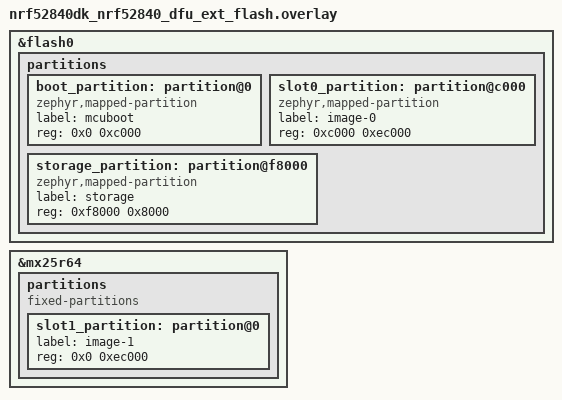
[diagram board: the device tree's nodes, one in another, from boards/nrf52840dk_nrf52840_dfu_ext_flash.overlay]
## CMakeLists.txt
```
# SPDX-License-Identifier: LicenseRef-Nordic-5-Clause

cmake_minimum_required(VERSION 3.13.1)
find_package(Zephyr REQUIRED HINTS $ENV{ZEPHYR_BASE})
project(mesh_dfu_target)

set(dfu_common_dir ${ZEPHYR_NRF_MODULE_DIR}/samples/bluetooth/mesh/dfu/common/src)

include_directories(
  ${dfu_common_dir}
  ${ZEPHYR_NRF_MODULE_DIR}/samples/bluetooth/mesh/common
)

FILE(GLOB app_sources src/*.c)
target_sources(app PRIVATE ${app_sources}
  ${dfu_common_dir}/dfu_target.c
)

target_sources_ifdef(CONFIG_NCS_SAMPLE_MCUMGR_BT_OTA_DFU app PRIVATE
  ${ZEPHYR_NRF_MODULE_DIR}/samples/bluetooth/mesh/common/smp_bt.c
)

target_link_libraries(app PRIVATE MCUBOOT_BOOTUTIL)
```

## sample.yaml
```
sample:
  name: Bluetooth Mesh DFU Target
common:
  tags:
    - bluetooth
    - ci_build
    - sysbuild
    - ci_samples_bluetooth
tests:
  sample.bluetooth.mesh_dfu_target:
    sysbuild: true
    build_only: true
    integration_platforms:
      - nrf54l15dk/nrf54l15/cpuapp
    platform_allow:
      - nrf54l15dk/nrf54l15/cpuapp
      - nrf54l15dk/nrf54l10/cpuapp
      - nrf54lc10dk/nrf54lc10a/cpuapp
      - nrf54lm20dk/nrf54lm20a/cpuapp
  sample.bluetooth.mesh_dfu_target.dfu_ext_flash:
    sysbuild: true
    build_only: true
    integration_platforms:
      - nrf54l15dk/nrf54l15/cpuapp
    platform_allow:
      - nrf54l15dk/nrf54l15/cpuapp
    extra_args: FILE_SUFFIX=dfu_ext_flash
  sample.bluetooth.mesh_dfu_target.settings_ext_flash:
    sysbuild: true
    build_only: true
    integration_platforms:
      - nrf54l15dk/nrf54l15/cpuapp
    platform_allow:
      - nrf54l15dk/nrf54l15/cpuapp
      - nrf54l15dk/nrf54l10/cpuapp
    extra_args: FILE_SUFFIX=settings_ext_flash
```

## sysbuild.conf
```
#
# Copyright (c) 2023 Nordic Semiconductor
#
# SPDX-License-Identifier: LicenseRef-Nordic-5-Clause
#

SB_CONFIG_BOOTLOADER_MCUBOOT=y
SB_CONFIG_MERGED_HEX_FILES=y
SB_CONFIG_DFU_ZIP=y
SB_CONFIG_DFU_ZIP_BLUETOOTH_MESH_METADATA=y
SB_CONFIG_DFU_ZIP_BLUETOOTH_MESH_METADATA_FWID_MCUBOOT_VERSION=y
```

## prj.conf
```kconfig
#
# Copyright (c) 2021 Nordic Semiconductor ASA
#
# SPDX-License-Identifier: LicenseRef-Nordic-5-Clause
#

# General configuration
CONFIG_SYSTEM_WORKQUEUE_STACK_SIZE=2048
CONFIG_FLASH=y
CONFIG_FLASH_MAP=y
CONFIG_NVS=y
CONFIG_SETTINGS=y
CONFIG_NVS_LOOKUP_CACHE=y
CONFIG_SETTINGS_NVS_NAME_CACHE=y
CONFIG_HWINFO=y
CONFIG_DK_LIBRARY=y
CONFIG_BT_MESH_NODE_RESET_BUTTON=y
CONFIG_LOG=y

# Bootloader configuration
CONFIG_NCS_APPLICATION_BOOT_BANNER_STRING="Mesh DFU Target"
CONFIG_STREAM_FLASH=y
CONFIG_BOOTLOADER_MCUBOOT=y
CONFIG_IMG_MANAGER=y
CONFIG_MCUBOOT_IMG_MANAGER=y
CONFIG_MCUBOOT_GENERATE_CONFIRMED_IMAGE=y
CONFIG_MCUBOOT_IMGTOOL_SIGN_VERSION="1.0.0+0"
CONFIG_REBOOT=y

# Bluetooth configuration
CONFIG_BT=y
CONFIG_BT_DEVICE_NAME="Mesh DFU Target"
CONFIG_BT_L2CAP_TX_BUF_COUNT=8
CONFIG_BT_OBSERVER=y
CONFIG_BT_PERIPHERAL=y
CONFIG_BT_SETTINGS=y

# Disable unused Bluetooth features
CONFIG_BT_CTLR_LE_ENC=n
CONFIG_BT_DATA_LEN_UPDATE=n
CONFIG_BT_PHY_UPDATE=n
CONFIG_BT_CTLR_CHAN_SEL_2=n
CONFIG_BT_CTLR_PRIVACY=n

# Bluetooth Mesh configuration
CONFIG_BT_MESH=y
CONFIG_BT_MESH_RELAY=y
CONFIG_BT_MESH_FRIEND=y
CONFIG_BT_MESH_MSG_CACHE_SIZE=256
CONFIG_BT_MESH_ADV_BUF_COUNT=128
CONFIG_BT_MESH_TX_SEG_MAX=14
CONFIG_BT_MESH_RX_SEG_MAX=14
CONFIG_BT_MESH_TX_SEG_MSG_COUNT=2
CONFIG_BT_MESH_RX_SEG_MSG_COUNT=2
CONFIG_BT_MESH_PB_GATT=y
CONFIG_BT_MESH_PB_ADV=y
CONFIG_BT_MESH_GATT_PROXY=y
CONFIG_BT_MESH_DK_PROV=y
CONFIG_BT_MESH_PROXY_USE_DEVICE_NAME=y
CONFIG_BT_MESH_MODEL_EXTENSIONS=y
CONFIG_BT_MESH_MODEL_EXTENSION_LIST_SIZE=1

# Bluetooth Mesh models
CONFIG_BT_MESH_BLOB_SRV=y
CONFIG_BT_MESH_BLOB_IO_FLASH=y
CONFIG_BT_MESH_DFU_SRV=y
CONFIG_BT_MESH_DFU_METADATA=y
CONFIG_BT_MESH_SAR_CFG_SRV=y

# Reconfigure transport SAR for DFU
# Increase probability of delivering segmented messages
CONFIG_BT_MESH_SAR_TX_UNICAST_RETRANS_COUNT=0x5
CONFIG_BT_MESH_SAR_TX_UNICAST_RETRANS_WITHOUT_PROG_COUNT=0x3
# Reduce amount of generated SegAcks
CONFIG_BT_MESH_SAR_RX_ACK_RETRANS_COUNT=0x0
CONFIG_BT_MESH_SAR_RX_ACK_DELAY_INC=0x7
CONFIG_BT_MESH_SAR_RX_SEG_INT_STEP=0xf
CONFIG_BT_MESH_SAR_RX_SEG_THRESHOLD=0x1f

# Debug configuration
CONFIG_BT_MESH_LOG_LEVEL_DBG=y
CONFIG_BT_MESH_MODEL_LOG_LEVEL_DBG=y
CONFIG_BT_MESH_DFU_LOG_LEVEL_DBG=y
CONFIG_BT_MESH_PROVISIONEE_LOG_LEVEL_INF=y

# Link Time Optimization. CONFIG_LTO depends on ISR_TABLES_LOCAL_DECLARATION
CONFIG_LTO=y
CONFIG_ISR_TABLES_LOCAL_DECLARATION=y
```

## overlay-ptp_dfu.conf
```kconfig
#
# Copyright (c) 2024 Nordic Semiconductor ASA
#
# SPDX-License-Identifier: LicenseRef-Nordic-5-Clause
#

# Enable point to point DFU over SMP
CONFIG_NCS_SAMPLE_MCUMGR_BT_OTA_DFU=y
CONFIG_NCS_SAMPLE_MCUMGR_BT_OTA_DFU_SPEEDUP=y

# Increase Extended Advertiser Set to advertise BT SMP service
CONFIG_BT_EXT_ADV_MAX_ADV_SET=6

# One extra connection for mesh GATT/proxy and one for SMP BT.
CONFIG_BT_MAX_CONN=3

# One extra identity for SMP service
CONFIG_BT_ID_MAX=2
```

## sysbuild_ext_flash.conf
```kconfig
#
# Copyright (c) 2025 Nordic Semiconductor ASA
#
# SPDX-License-Identifier: LicenseRef-Nordic-5-Clause
#

SB_CONFIG_BOOTLOADER_MCUBOOT=y
SB_CONFIG_PM_EXTERNAL_FLASH_MCUBOOT_SECONDARY=y
SB_CONFIG_DFU_ZIP=y
SB_CONFIG_DFU_ZIP_BLUETOOTH_MESH_METADATA=y
SB_CONFIG_DFU_ZIP_BLUETOOTH_MESH_METADATA_FWID_MCUBOOT_VERSION=y
```

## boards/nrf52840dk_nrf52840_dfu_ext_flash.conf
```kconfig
#
# Copyright (c) 2026 Nordic Semiconductor ASA
#
# SPDX-License-Identifier: LicenseRef-Nordic-5-Clause
#

# External flash support for nRF52840 DK
CONFIG_NORDIC_QSPI_NOR=y
```

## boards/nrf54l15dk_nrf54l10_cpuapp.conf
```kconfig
#
# Copyright (c) 2024 Nordic Semiconductor ASA
#
# SPDX-License-Identifier: LicenseRef-Nordic-5-Clause
#
################################################################################
# Application overlay - nrf54l10

CONFIG_SOC_FLASH_NRF_PARTIAL_ERASE=n
CONFIG_NVS=n
CONFIG_NVS_LOOKUP_CACHE=n
CONFIG_SETTINGS_NVS_NAME_CACHE=n
CONFIG_ZMS=y
CONFIG_SETTINGS_ZMS_CUSTOM_SECTOR_COUNT=y
CONFIG_SETTINGS_ZMS_SECTOR_COUNT=8
CONFIG_ZMS_LOOKUP_CACHE=y
CONFIG_ZMS_LOOKUP_CACHE_SIZE=512
```

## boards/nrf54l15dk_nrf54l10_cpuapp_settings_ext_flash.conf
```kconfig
#
# Copyright (c) 2025 Nordic Semiconductor ASA
#
# SPDX-License-Identifier: LicenseRef-Nordic-5-Clause
#
################################################################################
# Application overlay - nrf54l10

CONFIG_SOC_FLASH_NRF_PARTIAL_ERASE=n
CONFIG_NVS=n
CONFIG_NVS_LOOKUP_CACHE=n
CONFIG_SETTINGS_NVS_NAME_CACHE=n
CONFIG_ZMS=y
CONFIG_SETTINGS_ZMS_CUSTOM_SECTOR_COUNT=y
CONFIG_SETTINGS_ZMS_SECTOR_COUNT=8
CONFIG_ZMS_LOOKUP_CACHE=y
CONFIG_ZMS_LOOKUP_CACHE_SIZE=512
CONFIG_ZMS_LOOKUP_CACHE_FOR_SETTINGS=y
CONFIG_SYSTEM_WORKQUEUE_STACK_SIZE=4096
CONFIG_BT_RX_STACK_SIZE=5120
CONFIG_BT_MESH_SETTINGS_WORKQ_STACK_SIZE=1800

# External flash specific settings
CONFIG_GPIO=y
CONFIG_SPI=y
CONFIG_SPI_NOR=y
CONFIG_SPI_NOR_SFDP_DEVICETREE=y
CONFIG_SPI_NOR_FLASH_LAYOUT_PAGE_SIZE=4096
# QSPI drivers are enabled by default for some chips.
# Disable it explicitly to be sure QSPI is disabled.
CONFIG_NORDIC_QSPI_NOR=n
```

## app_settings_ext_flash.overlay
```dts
/* Copyright (c) 2025 Nordic Semiconductor ASA
 *
 * SPDX-License-Identifier: LicenseRef-Nordic-5-Clause
 */

/delete-node/ &storage_partition;

&mx25r64 {
	status = "okay";

	partitions {
		compatible = "fixed-partitions";
		#address-cells = <1>;
		#size-cells = <1>;

		storage_partition: partition@0 {
			label = "storage";
			reg = <0x0 0x8000>;
		};
	};
};
```

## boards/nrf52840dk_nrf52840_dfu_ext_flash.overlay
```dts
/*
 * Copyright (c) 2026 Nordic Semiconductor ASA
 *
 * SPDX-License-Identifier: LicenseRef-Nordic-5-Clause
 */

/delete-node/ &boot_partition;
/delete-node/ &slot0_partition;
/delete-node/ &slot1_partition;
/delete-node/ &storage_partition;

&flash0 {
	partitions {
		boot_partition: partition@0 {
			compatible = "zephyr,mapped-partition";
			label = "mcuboot";
			reg = <0x0 0xc000>;
		};

		slot0_partition: partition@c000 {
			compatible = "zephyr,mapped-partition";
			label = "image-0";
			reg = <0xc000 0xec000>;
		};

		storage_partition: partition@f8000 {
			compatible = "zephyr,mapped-partition";
			label = "storage";
			reg = <0xf8000 0x8000>;
		};
	};
};

&mx25r64 {
	status = "okay";

	partitions {
		compatible = "fixed-partitions";
		#address-cells = <1>;
		#size-cells = <1>;

		slot1_partition: partition@0 {
			label = "image-1";
			reg = <0x0 0xec000>;
		};
	};
};
```

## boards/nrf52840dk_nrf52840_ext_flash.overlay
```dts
/* Copyright (c) 2025 Nordic Semiconductor ASA
 *
 * SPDX-License-Identifier: LicenseRef-Nordic-5-Clause
 */

&mx25r64 {
	status = "okay";
	nordic,pm-ext-flash = &mx25r64;
};
```

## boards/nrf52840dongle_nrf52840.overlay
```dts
/*
 * Copyright (c) 2026 Nordic Semiconductor ASA
 *
 * SPDX-License-Identifier: LicenseRef-Nordic-5-Clause
 */

/delete-node/ &boot_partition;
/delete-node/ &slot0_partition;
/delete-node/ &slot1_partition;
/delete-node/ &storage_partition;

&flash0 {
	partitions {
		nrf5_mbr: partition@0 {
			compatible = "zephyr,mapped-partition";
			label = "nrf5-mbr";
			reg = <0x0 0x1000>;
		};

		boot_partition: partition@1000 {
			compatible = "zephyr,mapped-partition";
			label = "mcuboot";
			reg = <0x1000 0x10000>;
		};

		slot0_partition: partition@11000 {
			compatible = "zephyr,mapped-partition";
			label = "image-0";
			reg = <0x11000 0x66000>;
		};

		slot1_partition: partition@77000 {
			compatible = "zephyr,mapped-partition";
			label = "image-1";
			reg = <0x77000 0x66000>;
		};

		storage_partition: partition@dd000 {
			compatible = "zephyr,mapped-partition";
			label = "storage";
			reg = <0xdd000 0x3000>;
		};

		legacy_bootloader_storage: partition@e0000 {
			compatible = "zephyr,mapped-partition";
			label = "legacy-bootloader-storage";
			reg = <0xe0000 0x20000>;
		};
	};
};
```

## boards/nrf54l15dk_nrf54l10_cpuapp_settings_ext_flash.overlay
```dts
/*
 * Copyright (c) 2026 Nordic Semiconductor ASA
 *
 * SPDX-License-Identifier: LicenseRef-Nordic-5-Clause
 */

/delete-node/ &boot_partition;
/delete-node/ &slot0_partition;
/delete-node/ &slot1_partition;
/delete-node/ &storage_partition;

&cpuapp_rram {
	partitions {
		boot_partition: partition@0 {
			compatible = "zephyr,mapped-partition";
			label = "mcuboot";
			reg = <0x0 0xe000>;
		};

		slot0_partition: partition@e000 {
			compatible = "zephyr,mapped-partition";
			label = "image-0";
			reg = <0xe000 0x73000>;
		};

		slot1_partition: partition@81000 {
			compatible = "zephyr,mapped-partition";
			label = "image-1";
			reg = <0x81000 0x73000>;
		};
	};
};

&mx25r64 {
	status = "okay";

	partitions {
		compatible = "fixed-partitions";
		#address-cells = <1>;
		#size-cells = <1>;

		storage_partition: partition@0 {
			label = "storage";
			reg = <0x0 0x8000>;
		};
	};
};
```

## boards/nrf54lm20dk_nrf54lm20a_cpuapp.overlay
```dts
/*
 * Copyright (c) 2026 Nordic Semiconductor ASA
 *
 * SPDX-License-Identifier: LicenseRef-Nordic-5-Clause
 */

/delete-node/ &boot_partition;
/delete-node/ &slot0_partition;
/delete-node/ &slot1_partition;
/delete-node/ &storage_partition;

&cpuapp_rram {
	partitions {
		boot_partition: partition@0 {
			compatible = "zephyr,mapped-partition";
			label = "mcuboot";
			reg = <0x0 0xe000>;
		};

		slot0_partition: partition@e000 {
			compatible = "zephyr,mapped-partition";
			label = "image-0";
			reg = <0xe000 0xe7000>;
		};

		slot1_partition: partition@f5000 {
			compatible = "zephyr,mapped-partition";
			label = "image-1";
			reg = <0xf5000 0xe7000>;
		};

		storage_partition: partition@1dd000 {
			compatible = "zephyr,mapped-partition";
			label = "storage";
			reg = <0x1dd000 0x8000>;
		};
	};
};
```

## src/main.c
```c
/*
 * Copyright (c) 2021 Nordic Semiconductor ASA
 *
 * SPDX-License-Identifier: LicenseRef-Nordic-5-Clause
 */

/** @file
 *  @brief Bluetooth Mesh DFU Target role sample
 */
#include <zephyr/kernel.h>
#include <bluetooth/mesh/dk_prov.h>
#include <zephyr/storage/flash_map.h>
#include <dk_buttons_and_leds.h>
#include <bluetooth/mesh/node_reset_button.h>
#include <zephyr/bluetooth/bluetooth.h>
#include <zephyr/bluetooth/mesh.h>
#include "dfu_target.h"
#if defined(CONFIG_NCS_SAMPLE_MCUMGR_BT_OTA_DFU)
#include "smp_bt.h"
#endif

static struct bt_mesh_blob_io_flash blob_flash_stream;

/* Set up a repeating delayed work to blink the DK's LEDs when attention is
 * requested.
 */
static struct k_work_delayable attention_blink_work;
static bool attention;

static void attention_blink(struct k_work *work)
{
	static int idx;
	const uint8_t pattern[] = {
#if DT_NODE_EXISTS(DT_ALIAS(led0))
		BIT(0),
#endif
#if DT_NODE_EXISTS(DT_ALIAS(led1))
		BIT(1),
#endif
#if DT_NODE_EXISTS(DT_ALIAS(led2))
		BIT(2),
#endif
#if DT_NODE_EXISTS(DT_ALIAS(led3))
		BIT(3),
#endif
	};

	if (attention) {
		dk_set_leds(pattern[idx++ % ARRAY_SIZE(pattern)]);
		k_work_reschedule(&attention_blink_work, K_MSEC(30));
	} else {
		dk_set_leds(DK_NO_LEDS_MSK);
	}
}

static void attention_on(const struct bt_mesh_model *mod)
{
	attention = true;
	k_work_reschedule(&attention_blink_work, K_NO_WAIT);
}

static void attention_off(const struct bt_mesh_model *mod)
{
	/* Will stop rescheduling blink timer */
	attention = false;
}

static const struct bt_mesh_health_srv_cb health_srv_cb = {
	.attn_on = attention_on,
	.attn_off = attention_off,
};

static struct bt_mesh_health_srv health_srv = {
	.cb = &health_srv_cb,
};

BT_MESH_HEALTH_PUB_DEFINE(health_pub, 0);

static struct bt_mesh_model models[] = {
	BT_MESH_MODEL_CFG_SRV,
	BT_MESH_MODEL_HEALTH_SRV(&health_srv, &health_pub),
	BT_MESH_MODEL_DFU_SRV(&dfu_srv)
};

static struct bt_mesh_elem elements[] = {
	BT_MESH_ELEM(1, models, BT_MESH_MODEL_NONE),
};

static const struct bt_mesh_comp comp = {
	.cid = CONFIG_BT_COMPANY_ID,
	.elem = elements,
	.elem_count = ARRAY_SIZE(elements),
};

static void bt_ready(int err)
{
	if (err) {
		printk("Bluetooth init failed (err %d)\n", err);
		return;
	}

	printk("Bluetooth initialized\n");

	err = dk_leds_init();
	if (err) {
		printk("Initializing LEDs failed (err %d)\n", err);
		return;
	}

	if (IS_ENABLED(CONFIG_BT_MESH_NODE_RESET_BUTTON)) {
		err = dk_buttons_init(NULL);
		if (err) {
			printk("Initializing buttons failed (err %d)\n", err);
			return;
		}

		bt_mesh_node_reset_button_init();
	}

	err = bt_mesh_init(bt_mesh_dk_prov_init(), &comp);
	if (err) {
		printk("Initializing mesh failed (err %d)\n", err);
		return;
	}

	if (IS_ENABLED(CONFIG_SETTINGS)) {
		settings_load();
	}

	bt_mesh_prov_enable(BT_MESH_PROV_ADV | BT_MESH_PROV_GATT);

	printk("Mesh initialized\n");

#if defined(CONFIG_NCS_SAMPLE_MCUMGR_BT_OTA_DFU)
	/* Start advertising SMP BT service. */
	err = smp_dfu_init();
	if (err) {
		printk("SMP initialization failed (err: %d)\n", err);
	}
#endif

	/* Confirm the image and mark it as applied after the mesh started. */
	dfu_target_image_confirm();
}

int main(void)
{
	int err;

	printk("Initializing...\n");

	err = bt_mesh_blob_io_flash_init(&blob_flash_stream, PARTITION_ID(slot1_partition),
					 0);
	if (err) {
		printk("Failed to init BLOB IO Flash module: %d\n", err);
		return 1;
	}

	k_work_init_delayable(&attention_blink_work, attention_blink);
	dfu_target_init(&blob_flash_stream);

	err = bt_enable(bt_ready);
	if (err) {
		printk("Bluetooth init failed (err %d)\n", err);
		return 1;
	}

	return 0;
}
```
